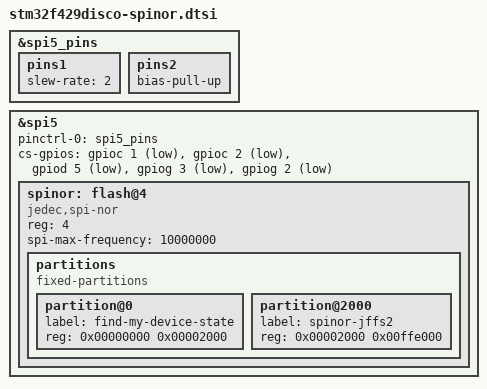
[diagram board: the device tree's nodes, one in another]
/*
 * Winbond W25Q128FV sharing SPI5 with onboard devices and optional W5500/NAND.
 * PF7=SCK, PF8=MISO, PF9=MOSI, and PG2=active-low chip select.
 */

&spi5_pins {
	pins1 {
		slew-rate = <2>;
	};

	pins2 {
		bias-pull-up;
	};
};

&spi5 {
	status = "okay";
	pinctrl-names = "default";
	pinctrl-0 = <&spi5_pins>;
	/* CS0: gyroscope; CS1: LCD; CS2: W5500; CS3: NAND; CS4: NOR. */
	cs-gpios = <&gpioc 1 GPIO_ACTIVE_LOW>,
		     <&gpioc 2 GPIO_ACTIVE_LOW>,
		     <&gpiod 5 GPIO_ACTIVE_LOW>,
		     <&gpiog 3 GPIO_ACTIVE_LOW>,
		     <&gpiog 2 GPIO_ACTIVE_LOW>;

	spinor: flash@4 {
		compatible = "jedec,spi-nor";
		reg = <4>;
		spi-max-frequency = <10000000>;

		partitions {
			compatible = "fixed-partitions";
			#address-cells = <1>;
			#size-cells = <1>;

			partition@0 {
				label = "find-my-device-state";
				reg = <0x00000000 0x00002000>;
			};

			partition@2000 {
				label = "spinor-jffs2";
				reg = <0x00002000 0x00ffe000>;
			};
		};
	};
};
